# PWMSS1_CFG_local register map
Vendor: Texas Instruments
Peripheral module from a debugger description file (folder DRA72x).
Registers are 32-bit, read-only, no defined reset value unless marked. A register's access mark holds for its fields unless they carry their own. Offsets are as the file gives them; lines under a group give offsets from that group; [hi:lo] are bit positions; {n}, {i} and the like mark numbered series; 'fields as' and 'values as' point back to an identical list; <NAME> marks a mode.

## PWMSS1_CFG
0x00 PWMSS_IDVER — IP Revision Register
  [31:0] REVISION — IP Revision value
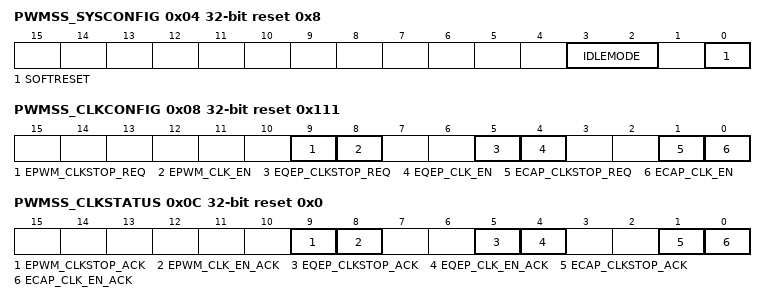
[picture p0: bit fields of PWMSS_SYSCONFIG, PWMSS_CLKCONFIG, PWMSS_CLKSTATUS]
0x04 PWMSS_SYSCONFIG access per field reset 0x8 — This register controls the PWMSSn (where n= 1 to 3) local Idle mode clock management and software reset
  [3:2] IDLEMODE rw — Configuration of the local target state management mode. By definition, the target can handle read/write transaction as long as it is out of IDLE state.
    0=Force-idle mode: The local target IDLE state follows (acknowledges) the system idle requests unconditionally, that is, regardless of the internal requirements of th e IP module. Backup mode, for debug only.; 1=no (No-idle mode: The local target never enters IDLE state. Backup mode, for debug only.); 2=Smart-idle mode: The local target IDLE state eventually follows (acknowledges) the system idle requests, depending on the internal requirements of the IP module. IP module does not generate (IRQ- or DMA-request-related) wakeup events.; 3=smart (Reserved)
  [0] SOFTRESET rw — Software reset : 0x0 : Software reset is completed 0x1: Software reset assertion
0x08 PWMSS_CLKCONFIG access per field reset 0x111 — The clock configuration register is used in the PWMSSn (where n = 1 to 3) for clkstop req and clk_en control to the ePWM/ eHRPWM, eCAP and eQEP submodules within the PWMSSn subsystem.Note: PWMSS Modules Local Clock Gating feature is not supported. This register should not be modified. Clock gating functionality is controlled by PRCM.
  [9] EPWM_CLKSTOP_REQ rw — This bit controls the clock stop input to the ePWM / eHRPWM module : 0: No effect 1: A request to stop interface clock to the module is asserted
  [8] EPWM_CLK_EN rw — This bit controls the interface clock enable (clk_en) input to the ePWM / eHRPWM module: 0: No effect 1: Enables the interface clock to the module
  [5] EQEP_CLKSTOP_REQ rw — This bit controls the clock stop input to the eQEP module : 0: No effect 1: A request to stop interface clock to the module is asserted
  [4] EQEP_CLK_EN rw — This bit controls the interface clock enable (clk_en) input to the eQEP module : 0: No effect 1: Enables the interface clock to the module
  [1] ECAP_CLKSTOP_REQ rw — This bit controls the clock stop input to the eCAP module : 0: No effect 1: A request to stop interface clock to the module is asserted
  [0] ECAP_CLK_EN rw — This bit controls the interface clock enable (clk_en) input to the eCAP module : 0: No effect 1: Enables the interface clock to the module
0x0C PWMSS_CLKSTATUS reset 0x0 — The clock status register is used in the PWMSSn (where n = 1 to 3) to indicate clock stop acknowledge (clkstop_ack) and clock enable (clk_en) acknowledge status for the ePWM/ eHRPWM, eCAP and eQEP submodules within the PWMSSn subsystem.Note:PWMSS Modules Local Clock Gating feature is not supported. Clock gating functionality is controlled by PRCM.
  [9] EPWM_CLKSTOP_ACK — This bit is the clkstop_req_ack status output of the ePWM / eHRPWM module : 0: No interface clock stop acknowledged 1: Interface clock stop request is acknowledged for the module
  [8] EPWM_CLK_EN_ACK — This bit is the clk_en status output of the ePWM / eHRPWM module : 0: No clock enable request acknowledged 1: Interface clock enable request is acknowledged for the module
  [5] EQEP_CLKSTOP_ACK — This bit is the clkstop_req_ack status output of the eQEP module : 0: No interface clock stop acknowledged 1: Interface clock stop request is acknowledged for the module
  [4] EQEP_CLK_EN_ACK — This bit is the clk_en status output of the eQEP module : 0: No clock enable request acknowledged 1: Interface clock enable request is acknowledged for the module
  [1] ECAP_CLKSTOP_ACK — TThis bit is the clkstop_req_ack status output of the eCAP module : 0: No interface clock stop acknowledged 1: Interface clock stop request is acknowledged for the module
  [0] ECAP_CLK_EN_ACK — TThis bit is the clk_en status output of the eCAP module : 0: No clock enable request acknowledged 1: Interface clock enable request is acknowledged for the module
